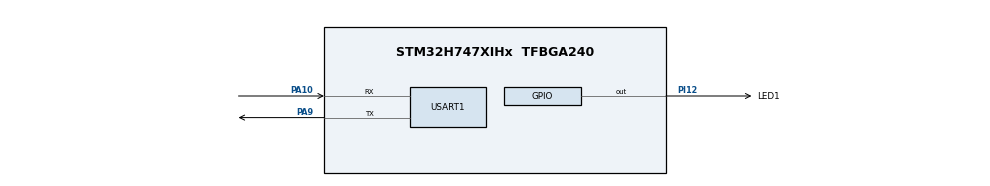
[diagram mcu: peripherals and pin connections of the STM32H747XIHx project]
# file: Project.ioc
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CORTEX_M7.AccessPermission-Cortex_Memory_Protection_Unit_Region1_Settings=MPU_REGION_FULL_ACCESS
CORTEX_M7.BaseAddress-Cortex_Memory_Protection_Unit_Region1_Settings=SDRAM_DEVICE_ADDR
CORTEX_M7.CPU_DCache=Enabled
CORTEX_M7.CPU_ICache=Enabled
CORTEX_M7.DisableExec-Cortex_Memory_Protection_Unit_Region0_Settings=MPU_INSTRUCTION_ACCESS_DISABLE
CORTEX_M7.Enable-Cortex_Memory_Protection_Unit_Region0_Settings=MPU_REGION_ENABLE
CORTEX_M7.Enable-Cortex_Memory_Protection_Unit_Region1_Settings=MPU_REGION_ENABLE
CORTEX_M7.IsCacheable-Cortex_Memory_Protection_Unit_Region1_Settings=MPU_ACCESS_CACHEABLE
CORTEX_M7.IsShareable-Cortex_Memory_Protection_Unit_Region0_Settings=MPU_ACCESS_SHAREABLE
CORTEX_M7.MPU_Control=MPU_PRIVILEGED_DEFAULT
CORTEX_M7.Size-Cortex_Memory_Protection_Unit_Region0_Settings=MPU_REGION_SIZE_4GB
CORTEX_M7.Size-Cortex_Memory_Protection_Unit_Region1_Settings=MPU_REGION_SIZE_32MB
CORTEX_M7.SubRegionDisable-Cortex_Memory_Protection_Unit_Region0_Settings=0x87
CortexM4.IPs=BDMA,DMA,FATFS_M4\:I,FREERTOS_M4\:I,IWDG2\:I,MDMA,NVIC2\:I,RCC,USB_DEVICE_M4\:I,USB_HOST_M4\:I,WWDG2\:I,DEBUG,PDM2PCM_M4\:I,PWR,RESMGR_UTILITY,SYS_M4\:I,CORTEX_M4\:I,OPENAMP_M4\:I,VREFBUF,GPIO
CortexM7.IPs=BDMA\:I,DMA\:I,FATFS_M7\:I,FREERTOS_M7\:I,IWDG1\:I,MDMA\:I,NVIC1\:I,RCC\:I,USB_DEVICE_M7\:I,USB_HOST_M7\:I,WWDG1\:I,CORTEX_M7\:I,DEBUG\:I,PDM2PCM_M7\:I,PWR\:I,RESMGR_UTILITY\:I,SYS\:I,OPENAMP_M7\:I,VREFBUF\:I,GPIO\:I,USART1\:I,STMicroelectronics.X-CUBE-AI.9.0.0_M7\:I,CRC\:I
CortexM7.Pins=PI12
Mcu.Family=STM32H7
Mcu.Name=STM32H747XIHx
Mcu.Package=TFBGA240
NVIC1.PriorityGroup=NVIC_PRIORITYGROUP_4
NVIC2.PriorityGroup=NVIC_PRIORITYGROUP_4
PA10.Mode=Asynchronous
PA10.PinAttribute=CortexM7
PA10.Signal=USART1_RX
PA13\ (JTMS/SWDIO).Mode=Serial_Wire
PA13\ (JTMS/SWDIO).PinAttribute=CortexM7
PA13\ (JTMS/SWDIO).Signal=DEBUG_JTMS-SWDIO
PA14\ (JTCK/SWCLK).Mode=Serial_Wire
PA14\ (JTCK/SWCLK).PinAttribute=CortexM7
PA14\ (JTCK/SWCLK).Signal=DEBUG_JTCK-SWCLK
PA9.Mode=Asynchronous
PA9.PinAttribute=CortexM7
PA9.Signal=USART1_TX
PC14-OSC32_IN\ (OSC32_IN).Mode=LSE-External-Oscillator
PC14-OSC32_IN\ (OSC32_IN).PinAttribute=Free
PC14-OSC32_IN\ (OSC32_IN).Signal=RCC_OSC32_IN
PC15-OSC32_OUT\ (OSC32_OUT).Mode=LSE-External-Oscillator
PC15-OSC32_OUT\ (OSC32_OUT).PinAttribute=Free
PC15-OSC32_OUT\ (OSC32_OUT).Signal=RCC_OSC32_OUT
PH0-OSC_IN\ (PH0).Mode=HSE-External-Oscillator
PH0-OSC_IN\ (PH0).PinAttribute=Free
PH0-OSC_IN\ (PH0).Signal=RCC_OSC_IN
PH1-OSC_OUT\ (PH1).Mode=HSE-External-Oscillator
PH1-OSC_OUT\ (PH1).PinAttribute=Free
PH1-OSC_OUT\ (PH1).Signal=RCC_OSC_OUT
PI12.GPIO_Label=LED1
PI12.PinAttribute=CortexM7
PI12.Signal=GPIO_Output
ProjectManager.HeapSize=M4-0x800,M7-0x800
ProjectManager.StackSize=M4-0x800,M7-0x800
ProjectManager.TargetToolchain=MDK-ARM V5.32
RCC.ADCFreq_Value=75000000
RCC.APB1Freq_Value=100000000
RCC.APB2Freq_Value=100000000
RCC.APB3Freq_Value=100000000
RCC.APB4Freq_Value=100000000
RCC.CortexFreq_Value=400000000
RCC.D1PPRE=RCC_APB3_DIV2
RCC.D2PPRE1=RCC_APB1_DIV2
RCC.D2PPRE2=RCC_APB2_DIV2
RCC.D3PPRE=RCC_APB4_DIV2
RCC.DIVM1=2
RCC.DIVM2=2
RCC.DIVN1=64
RCC.DIVN2=12
RCC.HCLKFreq_Value=200000000
RCC.HPRE=RCC_HCLK_DIV2
RCC.PLL2FRACN=0
RCC.PLLFRACN=0
RCC.PLLSourceVirtual=RCC_PLLSOURCE_HSE
RCC.PWR_Regulator_Voltage_Scale=PWR_REGULATOR_VOLTAGE_SCALE1
RCC.SYSCLKFreq_VALUE=400000000
RCC.SYSCLKSource=RCC_SYSCLKSOURCE_PLLCLK
RCC.SupplySource=PWR_DIRECT_SMPS_SUPPLY
RCC.USBFreq_Value=400000000
STMicroelectronics.X-CUBE-AI.9.0.0_M7.ActivationBufferSizeList=11064
STMicroelectronics.X-CUBE-AI.9.0.0_M7.ActivationBuffers=pool0
STMicroelectronics.X-CUBE-AI.9.0.0_M7.ActivationNames=pool0
STMicroelectronics.X-CUBE-AI.9.0.0_M7.ActivationSizes=AI_NETWORK_DATA_ACTIVATION_1_SIZE
STMicroelectronics.X-CUBE-AI.9.0.0_M7.HeapSize=0x800
STMicroelectronics.X-CUBE-AI.9.0.0_M7.InternalRamActivationBufferMaxSize=AI_NETWORK_DATA_ACTIVATIONS_SIZE
STMicroelectronics.X-CUBE-AI.9.0.0_M7.LatestDirectoryUsed-6234248c4004abe7d7212880ea0172928cda6f889b609eae4421626e04a52cb4=C\:\\Users\\Lenovo\\Documents
STMicroelectronics.X-CUBE-AI.9.0.0_M7.MaximumNumberOfInputLayer=1
STMicroelectronics.X-CUBE-AI.9.0.0_M7.MaximumNumberOfOutputLayer=1
STMicroelectronics.X-CUBE-AI.9.0.0_M7.MaximumSizeOfInputLayer=1
STMicroelectronics.X-CUBE-AI.9.0.0_M7.MaximumSizeOfOutputLayer=1
STMicroelectronics.X-CUBE-AI.9.0.0_M7.ModelActualCompression-6234248c4004abe7d7212880ea0172928cda6f889b609eae4421626e04a52cb4=0.0
STMicroelectronics.X-CUBE-AI.9.0.0_M7.ModelCompression-6234248c4004abe7d7212880ea0172928cda6f889b609eae4421626e04a52cb4=None
STMicroelectronics.X-CUBE-AI.9.0.0_M7.ModelFlashOccupation-6234248c4004abe7d7212880ea0172928cda6f889b609eae4421626e04a52cb4=46304
STMicroelectronics.X-CUBE-AI.9.0.0_M7.ModelHashList=6234248c4004abe7d7212880ea0172928cda6f889b609eae4421626e04a52cb4
STMicroelectronics.X-CUBE-AI.9.0.0_M7.ModelKind-6234248c4004abe7d7212880ea0172928cda6f889b609eae4421626e04a52cb4=ONNX
STMicroelectronics.X-CUBE-AI.9.0.0_M7.ModelMacc-6234248c4004abe7d7212880ea0172928cda6f889b609eae4421626e04a52cb4=481480
STMicroelectronics.X-CUBE-AI.9.0.0_M7.ModelName-6234248c4004abe7d7212880ea0172928cda6f889b609eae4421626e04a52cb4=network
STMicroelectronics.X-CUBE-AI.9.0.0_M7.ModelNameList=network
STMicroelectronics.X-CUBE-AI.9.0.0_M7.ModelRamOccupation-6234248c4004abe7d7212880ea0172928cda6f889b609eae4421626e04a52cb4=11064
STMicroelectronics.X-CUBE-AI.9.0.0_M7.ModelStructureFile-6234248c4004abe7d7212880ea0172928cda6f889b609eae4421626e04a52cb4=C\:\\Users\\Lenovo\\Documents\\model.onnx
STMicroelectronics.X-CUBE-AI.9.0.0_M7.ModelType-6234248c4004abe7d7212880ea0172928cda6f889b609eae4421626e04a52cb4=STM32Cube.AI MCU runtime
STMicroelectronics.X-CUBE-AI.9.0.0_M7.ReadyForCodeGeneration=true
STMicroelectronics.X-CUBE-AI.9.0.0_M7.StackSize=0x800
STMicroelectronics.X-CUBE-AI.9.0.0_M7.WorkingBufferStartAddrList=0xFFFFFFFF
STMicroelectronics.X-CUBE-AI.9.0.0_M7.XAaCUBEAaAICcArtificialOoIntelligenceJjCore=true
STMicroelectronics.X-CUBE-AI.9.0.0_M7.copyWeightToRam=false
STMicroelectronics.X-CUBE-AI.9.0.0_M7.customLayerConfigEnabled=false
STMicroelectronics.X-CUBE-AI.9.0.0_M7.noOnnxIoTranspose=false
STMicroelectronics.X-CUBE-AI.9.0.0_M7.useInputAllocation=true
STMicroelectronics.X-CUBE-AI.9.0.0_M7.useOutputAllocation=true
USART1.VirtualMode-Asynchronous=VM_ASYNC
VP_CRC_VS_CRC.Mode=CRC_Activate
VP_STMicroelectronics.X-CUBE-AI_M7_VS_ArtificialOoIntelligenceJjXAaCUBEAaAI_9.0.0.Mode=ArtificialOoIntelligenceJjXAaCUBEAaAI
VP_SYS_M4_VS_Systick.Mode=SysTick
board=STM32H747I-DISCO

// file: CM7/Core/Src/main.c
/* USER CODE BEGIN Header */
/**
  ******************************************************************************
  * @file           : main.c
  * @brief          : Main program body
  ******************************************************************************
  * @attention
  *
  * Copyright (c) 2024 STMicroelectronics.
  * All rights reserved.
  *
  * This software is licensed under terms that can be found in the LICENSE file
  * in the root directory of this software component.
  * If no LICENSE file comes with this software, it is provided AS-IS.
  *
  ******************************************************************************
  */
/* USER CODE END Header */
#include "main.h"
#include "usart.h"
#include "gpio.h"
#include "network.h"
#include "network_data.h"
#include "crc.h"
/* USER CODE BEGIN Includes */
#include "stm32h747i_discovery.h"
#include "stm32h747i_discovery_lcd.h"
#include "stm32h747i_discovery_sdram.h"
#include "stm32h747i_discovery_bus.h"
#include "stm32h747i_discovery_ts.h"
#include "stm32_lcd.h"
#include "stm32_lcd.h"

#include <string.h>
#include <stdio.h>
/* USER CODE END Includes */

/* USER CODE BEGIN PTD */
#define LCD_FRAME_BUFFER        0xD0000000

extern LTDC_HandleTypeDef hlcd_ltdc;
static DMA2D_HandleTypeDef   hdma2d;
extern DSI_HandleTypeDef hlcd_dsi;
DSI_VidCfgTypeDef hdsivideo_handle;
DSI_CmdCfgTypeDef CmdCfg;
DSI_LPCmdTypeDef LPCmd;
DSI_PLLInitTypeDef dsiPllInit;
static RCC_PeriphCLKInitTypeDef  PeriphClkInitStruct;
OTM8009A_Object_t *pObj;

TS_Init_t *hTS;
/* Global handle to reference the instantiated C-model */
static ai_handle network = AI_HANDLE_NULL;

/* Global c-array to handle the activations buffer */
AI_ALIGNED(32)
static ai_u8 activations[AI_NETWORK_DATA_ACTIVATIONS_SIZE];

/* Array to store the data of the input tensor */
AI_ALIGNED(32)
static ai_float input_data[784];
/* or static ai_u8 in_data[AI_NETWORK_IN_1_SIZE_BYTES]; */

/* c-array to store the data of the output tensor */
AI_ALIGNED(32)
static ai_float output_data[10];
/* static ai_u8 out_data[AI_NETWORK_OUT_1_SIZE_BYTES]; */

/* Array of pointer to manage the model's input/output tensors */
static ai_buffer *ai_input;
static ai_buffer *ai_output;

/* USER CODE END PTD */

/* USER CODE BEGIN PD */

#ifndef HSEM_ID_0
#define HSEM_ID_0 (0U) /* HW semaphore 0*/
#endif

/* USER CODE END PD */

/* USER CODE BEGIN PM */
#define VSYNC               1
#define VBP                 1
#define VFP                 1
#define VACT                480
#define HSYNC               1
#define HBP                 1
#define HFP                 1
#define HACT                800

#define LAYER0_ADDRESS               (LCD_FB_START_ADDRESS)

/* USER CODE END PM */

/* USER CODE BEGIN PV */

uint8_t My_String[60];
TS_State_t  TS_State = {0};
float in_data [28*28];

/* USER CODE END PV */

void SystemClock_Config(void);
static void MPU_Config(void);
/* USER CODE BEGIN PFP */
static void CopyBuffer(uint32_t *pSrc,
                           uint32_t *pDst,
                           uint16_t x,
                           uint16_t y,
                           uint16_t xsize,
                           uint16_t ysize);
static uint8_t LCD_Init(void);
void LTDC_Init(void);

static void LCD_LayertInit(uint16_t LayerIndex, uint32_t Address);
static int32_t DSI_IO_Write(uint16_t ChannelNbr, uint16_t Reg, uint8_t *pData, uint16_t Size);
static int32_t DSI_IO_Read(uint16_t ChannelNbr, uint16_t Reg, uint8_t *pData, uint16_t Size);
int32_t LCD_GetXSize(uint32_t Instance, uint32_t *XSize);
int32_t LCD_GetYSize(uint32_t Instance, uint32_t *YSize);
void LCD_MspInit(void);

static void LCD_BriefDisplay(void);

const LCD_UTILS_Drv_t LCD_UTIL_Driver =
{
  BSP_LCD_DrawBitmap,
  BSP_LCD_FillRGBRect,
  BSP_LCD_DrawHLine,
  BSP_LCD_DrawVLine,
  BSP_LCD_FillRect,
  BSP_LCD_ReadPixel,
  BSP_LCD_WritePixel,
  LCD_GetXSize,
  LCD_GetYSize,
  BSP_LCD_SetActiveLayer,
  BSP_LCD_GetPixelFormat
};
int aiInit(void) {
  ai_error err;

  /* Create and initialize the c-model *//*??????c-model */
  const ai_handle acts[] = { activations };
  err = ai_network_create_and_init(&network, acts, NULL);
  if (err.type != AI_ERROR_NONE) {};

  /* Reteive pointers to the model's input/output tensors *//*????????/???????*/
  ai_input = ai_network_inputs_get(network, NULL);
  ai_output = ai_network_outputs_get(network, NULL);

  return 0;
}
void AI_Run()
{
  ai_i32 batch;
  ai_error err;

  /* Update IO handlers with the data payload */
  ai_input[0].data = AI_HANDLE_PTR(input_data);
  ai_output[0].data = AI_HANDLE_PTR(output_data);

  batch = ai_network_run(network, ai_input, ai_output);
  if (batch != 1) {
    err = ai_network_get_error(network);
    Error_Handler();
  }
 }

/* USER CODE END PFP */

int main(void)
{

/* USER CODE BEGIN Boot_Mode_Sequence_0 */
  int32_t timeout;
/* USER CODE END Boot_Mode_Sequence_0 */

  /* MPU Configuration--------------------------------------------------------*/
  MPU_Config();

  /* Enable the CPU Cache */

  /* Enable I-Cache---------------------------------------------------------*/
  SCB_EnableICache();

  /* Enable D-Cache---------------------------------------------------------*/
  SCB_EnableDCache();

/* USER CODE BEGIN Boot_Mode_Sequence_1 */
  /* Wait until CPU2 boots and enters in stop mode or timeout*/
  timeout = 0xFFFF;
  while((__HAL_RCC_GET_FLAG(RCC_FLAG_D2CKRDY) != RESET) && (timeout-- > 0));
  if ( timeout < 0 )
  {
  Error_Handler();
  }
/* USER CODE END Boot_Mode_Sequence_1 */
  /* MCU Configuration--------------------------------------------------------*/

  /* Reset of all peripherals, Initializes the Flash interface and the Systick. */
  HAL_Init();

  /* Configure the system clock */
  SystemClock_Config();
/* USER CODE BEGIN Boot_Mode_Sequence_2 */
/* When system initialization is finished, Cortex-M7 will release Cortex-M4 by means of
HSEM notification */
/*HW semaphore Clock enable*/
__HAL_RCC_HSEM_CLK_ENABLE();
/*Take HSEM */
HAL_HSEM_FastTake(HSEM_ID_0);
/*Release HSEM in order to notify the CPU2(CM4)*/
HAL_HSEM_Release(HSEM_ID_0,0);
/* wait until CPU2 wakes up from stop mode */
timeout = 0xFFFF;
while((__HAL_RCC_GET_FLAG(RCC_FLAG_D2CKRDY) == RESET) && (timeout-- > 0));
if ( timeout < 0 )
{
Error_Handler();
}
/* USER CODE END Boot_Mode_Sequence_2 */

  /* Initialize all configured peripherals */
  MX_GPIO_Init();
  MX_USART1_UART_Init();
  MX_CRC_Init();
  aiInit();
  /* USER CODE BEGIN 2 */
  /* Initialize used Leds */
  BSP_LED_Init(LED3);

  /* Initialize the SDRAM */
  BSP_SDRAM_Init(0);

  /* Initialize the LCD   */
  if( LCD_Init() != BSP_ERROR_NONE)
  {
    Error_Handler();
  }

	/* Set the LCD Context */
  Lcd_Ctx[0].ActiveLayer = 0;
  Lcd_Ctx[0].PixelFormat = LCD_PIXEL_FORMAT_ARGB8888;
  Lcd_Ctx[0].BppFactor = 4; /* 4 Bytes Per Pixel for ARGB8888 */
  Lcd_Ctx[0].XSize = 800;
  Lcd_Ctx[0].YSize = 480;
  /* Disable DSI Wrapper in order to access and configure the LTDC */
  __HAL_DSI_WRAPPER_DISABLE(&hlcd_dsi);

  /* Initialize LTDC layer 0 iused for Hint */
  LCD_LayertInit(0, LCD_FRAME_BUFFER);
  UTIL_LCD_SetFuncDriver(&LCD_UTIL_Driver);

  /* Enable DSI Wrapper so DSI IP will drive the LTDC */
  __HAL_DSI_WRAPPER_ENABLE(&hlcd_dsi);

  /* Display example brief   */
  LCD_BriefDisplay();

  /*Refresh the LCD display*/
  HAL_DSI_Refresh(&hlcd_dsi);  //?üD?íê3éoó??2úéú?D??????è??D??·t??3ìDò??

  /* Touchscreen initialization */
	uint32_t ts_status = BSP_ERROR_NONE;
  uint32_t x_size, y_size;

  BSP_LCD_GetXSize(0, &x_size);
  BSP_LCD_GetYSize(0, &y_size);
  hTS->Width = x_size;
  hTS->Height = y_size;
  hTS->Orientation = TS_SWAP_XY | TS_SWAP_Y;
  hTS->Accuracy = 0;

  ts_status = BSP_TS_Init(0, hTS);
  if(ts_status == BSP_ERROR_NONE)
  {
    /* Display touch screen demo description */
		UTIL_LCD_FillRect(0, 0, 800, 120, UTIL_LCD_COLOR_WHITE);
		UTIL_LCD_FillRect(200, 40, 400, 50, UTIL_LCD_COLOR_RED);
		UTIL_LCD_FillRect(205, 45, 390, 40, UTIL_LCD_COLOR_BLUE);
		UTIL_LCD_DisplayStringAt(300,60,(uint8_t*) "Handwriting Predict", LEFT_MODE);
		UTIL_LCD_FillRect(50, 150, 280, 280, UTIL_LCD_COLOR_BLACK);  //ó?óú'??t?áê?D'
		UTIL_LCD_DisplayStringAt(400,350,(uint8_t*) "Guess:", LEFT_MODE); //ê?±e?á1???ê???×?'ó?é?ü
		//UTIL_LCD_DisplayStringAt(600,350,(uint8_t*) "Second Guess:", LEFT_MODE); //ê?±e?á1???ê?????'??é?ü
		UTIL_LCD_SetTextColor(UTIL_LCD_COLOR_YELLOW);
		UTIL_LCD_FillRect(400, 150, 150, 50, UTIL_LCD_COLOR_RED);   // è???°'??
		UTIL_LCD_FillRect(405, 155, 140, 40, UTIL_LCD_COLOR_BLUE);  // è???°'??
		UTIL_LCD_DisplayStringAt(405,170,(uint8_t*) "    CLEAR  ", LEFT_MODE);
		UTIL_LCD_FillRect(400, 250, 150, 50, UTIL_LCD_COLOR_RED);   // ?¤2a°'??
		UTIL_LCD_FillRect(405, 255, 140, 40, UTIL_LCD_COLOR_BLUE);  // ?¤2a°'??
		UTIL_LCD_DisplayStringAt(405,270,(uint8_t*) "   PREDICT ", LEFT_MODE);
		HAL_DSI_Refresh(&hlcd_dsi);  //?üD?íê3éoó??2úéú?D??????è??D??·t??3ìDò??
	}
  /* USER CODE END 2 */

  /* Infinite loop */
  /* USER CODE BEGIN WHILE */
  while (1)
  {
//      /* Check in polling mode in touch screen the touch status and coordinates */
//      /* of touches if touch occurred                                           */
      ts_status = BSP_TS_GetState(0, &TS_State);
      if(TS_State.TouchDetected)
      {
        /* One or dual touch have been detected          */
        /* Only take into account the first touch so far */
				if(TS_State.TouchX>50&&TS_State.TouchX<330&&TS_State.TouchY>150&&TS_State.TouchY<430)
				{
					in_data[(TS_State.TouchX-50)/10+((TS_State.TouchY-150)/10)*28]=(float)255;
          in_data[((TS_State.TouchX-50)/10+1)+((TS_State.TouchY-150)/10)*28]=(float)255;
          in_data[(TS_State.TouchX-50)/10+((TS_State.TouchY-150)/10+1)*28]=(float)255;
          in_data[((TS_State.TouchX-50)/10+1)+((TS_State.TouchY-150)/10+1)*28]=(float)255;
					UTIL_LCD_FillCircle(TS_State.TouchX,TS_State.TouchY,4, UTIL_LCD_COLOR_WHITE );
					HAL_DSI_Refresh(&hlcd_dsi);
				}
				else if(TS_State.TouchX>400&&TS_State.TouchX<550&&TS_State.TouchY>150&&TS_State.TouchY<200)
				{
					UTIL_LCD_FillRect(50, 150, 280, 280, UTIL_LCD_COLOR_BLACK);
					for(int i=0;i<784;i++){	in_data[i]=0;}
					HAL_DSI_Refresh(&hlcd_dsi);
					UTIL_LCD_FillRect(600, 350, 100, 100, UTIL_LCD_COLOR_WHITE);
				}
				else if(TS_State.TouchX>400&&TS_State.TouchX<550&&TS_State.TouchY>250&&TS_State.TouchY<300)
				{
					//???¯ê?D'ê?±e??·¨??'yíê3é?
					for(int i=0;i<784;i++){
						input_data[i]=in_data[i];
					}
					AI_Run();
					/*char s[]="0";
					int i,j,a=0,b=0;
					int k[28]={0};
					for(i=0;i<28;i++){
						for(j=0;j<28;j++){
							if(in_data[i*28+j]==1)
								k[i]++;
						}
						if(k[i]>1)
							a++;
					}*/
					float t;
					int num;
					num=0;
					t=output_data[0];
					for(int i;i<10;i++){
						if(output_data[i]>t){
							t=output_data[i];
							num=i;
						}
					}
					HAL_DSI_Refresh(&hlcd_dsi);
					if(num==0)
					  UTIL_LCD_DisplayStringAt(600,350,(uint8_t*) "0", LEFT_MODE);
					else if(num==1)
						UTIL_LCD_DisplayStringAt(600,350,(uint8_t*) "1", LEFT_MODE);
				  else if(num==2)
						UTIL_LCD_DisplayStringAt(600,350,(uint8_t*) "2", LEFT_MODE);
					else if(num==3)
						UTIL_LCD_DisplayStringAt(600,350,(uint8_t*) "3", LEFT_MODE);
					else if(num==4)
						UTIL_LCD_DisplayStringAt(600,350,(uint8_t*) "4", LEFT_MODE);
					else if(num==5)
						UTIL_LCD_DisplayStringAt(600,350,(uint8_t*) "5", LEFT_MODE);
					else if(num==6)
						UTIL_LCD_DisplayStringAt(600,350,(uint8_t*) "6", LEFT_MODE);
					else if(num==7)
						UTIL_LCD_DisplayStringAt(600,350,(uint8_t*) "7", LEFT_MODE);
					else if(num==8)
						UTIL_LCD_DisplayStringAt(600,350,(uint8_t*) "8", LEFT_MODE);
					else
						UTIL_LCD_DisplayStringAt(600,350,(uint8_t*) "9", LEFT_MODE);

					HAL_Delay(500);  //±ü?a°'??°'???à'????'?'DD?¤2a??
					HAL_DSI_Refresh(&hlcd_dsi);
				}
			}
    /* USER CODE END WHILE */

  }
}

void SystemClock_Config(void)
{
  RCC_OscInitTypeDef RCC_OscInitStruct = {0};
  RCC_ClkInitTypeDef RCC_ClkInitStruct = {0};

  /** Supply configuration update enable
  */
  HAL_PWREx_ConfigSupply(PWR_DIRECT_SMPS_SUPPLY);

  /** Configure the main internal regulator output voltage
  */
  __HAL_PWR_VOLTAGESCALING_CONFIG(PWR_REGULATOR_VOLTAGE_SCALE1);

  while(!__HAL_PWR_GET_FLAG(PWR_FLAG_VOSRDY)) {}

  /** Initializes the RCC Oscillators according to the specified parameters
  * in the RCC_OscInitTypeDef structure.
  */
  RCC_OscInitStruct.OscillatorType = RCC_OSCILLATORTYPE_HSE;
  RCC_OscInitStruct.HSEState = RCC_HSE_ON;
  RCC_OscInitStruct.PLL.PLLState = RCC_PLL_ON;
  RCC_OscInitStruct.PLL.PLLSource = RCC_PLLSOURCE_HSE;
  RCC_OscInitStruct.PLL.PLLM = 2;
  RCC_OscInitStruct.PLL.PLLN = 64;
  RCC_OscInitStruct.PLL.PLLP = 2;
  RCC_OscInitStruct.PLL.PLLQ = 2;
  RCC_OscInitStruct.PLL.PLLR = 2;
  RCC_OscInitStruct.PLL.PLLRGE = RCC_PLL1VCIRANGE_3;
  RCC_OscInitStruct.PLL.PLLVCOSEL = RCC_PLL1VCOWIDE;
  RCC_OscInitStruct.PLL.PLLFRACN = 0;
  if (HAL_RCC_OscConfig(&RCC_OscInitStruct) != HAL_OK)
  {
    Error_Handler();
  }

  /** Initializes the CPU, AHB and APB buses clocks
  */
  RCC_ClkInitStruct.ClockType = RCC_CLOCKTYPE_HCLK|RCC_CLOCKTYPE_SYSCLK
                              |RCC_CLOCKTYPE_PCLK1|RCC_CLOCKTYPE_PCLK2
                              |RCC_CLOCKTYPE_D3PCLK1|RCC_CLOCKTYPE_D1PCLK1;
  RCC_ClkInitStruct.SYSCLKSource = RCC_SYSCLKSOURCE_PLLCLK;
  RCC_ClkInitStruct.SYSCLKDivider = RCC_SYSCLK_DIV1;
  RCC_ClkInitStruct.AHBCLKDivider = RCC_HCLK_DIV2;
  RCC_ClkInitStruct.APB3CLKDivider = RCC_APB3_DIV2;
  RCC_ClkInitStruct.APB1CLKDivider = RCC_APB1_DIV2;
  RCC_ClkInitStruct.APB2CLKDivider = RCC_APB2_DIV2;
  RCC_ClkInitStruct.APB4CLKDivider = RCC_APB4_DIV2;

  if (HAL_RCC_ClockConfig(&RCC_ClkInitStruct, FLASH_LATENCY_2) != HAL_OK)
  {
    Error_Handler();
  }
}

/* USER CODE BEGIN 4 */
/**
  * @brief  Gets the LCD X size.
  * @param  Instance  LCD Instance
  * @param  XSize     LCD width
  * @retval BSP status
  */
int32_t LCD_GetXSize(uint32_t Instance, uint32_t *XSize)
{
  *XSize = Lcd_Ctx[0].XSize;

  return BSP_ERROR_NONE;
}

/**
  * @brief  Gets the LCD Y size.
  * @param  Instance  LCD Instance
  * @param  YSize     LCD Height
  * @retval BSP status
  */
int32_t LCD_GetYSize(uint32_t Instance, uint32_t *YSize)
{
  *YSize = Lcd_Ctx[0].YSize;

  return BSP_ERROR_NONE;
}
/**
  * @brief  End of Refresh DSI callback.
  * @param  hdsi: pointer to a DSI_HandleTypeDef structure that contains
  *               the configuration information for the DSI.
  * @retval None
  */
void HAL_DSI_EndOfRefreshCallback(DSI_HandleTypeDef *hdsi)
{
//  if(pending_buffer >= 0)
//  {
//    pending_buffer = -1;
//  }
}

/**
  * @brief  Initializes the DSI LCD.
  * The ititialization is done as below:
  *     - DSI PLL ititialization
  *     - DSI ititialization
  *     - LTDC ititialization
  *     - OTM8009A LCD Display IC Driver ititialization
  * @param  None
  * @retval LCD state
  */
static uint8_t LCD_Init(void)
{
  DSI_PHY_TimerTypeDef  PhyTimings;
  OTM8009A_IO_t              IOCtx;
  static OTM8009A_Object_t   OTM8009AObj;
  static void                *Lcd_CompObj = NULL;

  /* Toggle Hardware Reset of the DSI LCD using
     its XRES signal (active low) */
  BSP_LCD_Reset(0);

  /* Call first MSP Initialize only in case of first initialization
  * This will set IP blocks LTDC, DSI and DMA2D
  * - out of reset
  * - clocked
  * - NVIC IRQ related to IP blocks enabled
  */
  LCD_MspInit();

  /* LCD clock configuration */
  /* LCD clock configuration */
  /* PLL3_VCO Input = HSE_VALUE/PLL3M = 5 Mhz */
  /* PLL3_VCO Output = PLL3_VCO Input * PLL3N = 800 Mhz */
  /* PLLLCDCLK = PLL3_VCO Output/PLL3R = 800/19 = 42 Mhz */
  /* LTDC clock frequency = PLLLCDCLK = 42 Mhz */
  PeriphClkInitStruct.PeriphClockSelection = RCC_PERIPHCLK_LTDC;
  PeriphClkInitStruct.PLL3.PLL3M = 5;
  PeriphClkInitStruct.PLL3.PLL3N = 160;
  PeriphClkInitStruct.PLL3.PLL3FRACN = 0;
  PeriphClkInitStruct.PLL3.PLL3P = 2;
  PeriphClkInitStruct.PLL3.PLL3Q = 2;
  PeriphClkInitStruct.PLL3.PLL3R = 19;
  PeriphClkInitStruct.PLL3.PLL3VCOSEL = RCC_PLL3VCOWIDE;
  PeriphClkInitStruct.PLL3.PLL3RGE = RCC_PLL3VCIRANGE_2;
  HAL_RCCEx_PeriphCLKConfig(&PeriphClkInitStruct);

  /* Base address of DSI Host/Wrapper registers to be set before calling De-Init */
  hlcd_dsi.Instance = DSI;

  HAL_DSI_DeInit(&(hlcd_dsi));

  dsiPllInit.PLLNDIV  = 100;
  dsiPllInit.PLLIDF   = DSI_PLL_IN_DIV5;
  dsiPllInit.PLLODF  = DSI_PLL_OUT_DIV1;

  hlcd_dsi.Init.NumberOfLanes = DSI_TWO_DATA_LANES;
  hlcd_dsi.Init.TXEscapeCkdiv = 0x4;

  HAL_DSI_Init(&(hlcd_dsi), &(dsiPllInit));

  /* Configure the DSI for Command mode */
  CmdCfg.VirtualChannelID      = 0;
  CmdCfg.HSPolarity            = DSI_HSYNC_ACTIVE_HIGH;
  CmdCfg.VSPolarity            = DSI_VSYNC_ACTIVE_HIGH;
  CmdCfg.DEPolarity            = DSI_DATA_ENABLE_ACTIVE_HIGH;
  CmdCfg.ColorCoding           = DSI_RGB888;
  CmdCfg.CommandSize           = HACT;
  CmdCfg.TearingEffectSource   = DSI_TE_DSILINK;
  CmdCfg.TearingEffectPolarity = DSI_TE_RISING_EDGE;
  CmdCfg.VSyncPol              = DSI_VSYNC_FALLING;
  CmdCfg.AutomaticRefresh      = DSI_AR_DISABLE;
  CmdCfg.TEAcknowledgeRequest  = DSI_TE_ACKNOWLEDGE_ENABLE;
  HAL_DSI_ConfigAdaptedCommandMode(&hlcd_dsi, &CmdCfg);

  LPCmd.LPGenShortWriteNoP    = DSI_LP_GSW0P_ENABLE;
  LPCmd.LPGenShortWriteOneP   = DSI_LP_GSW1P_ENABLE;
  LPCmd.LPGenShortWriteTwoP   = DSI_LP_GSW2P_ENABLE;
  LPCmd.LPGenShortReadNoP     = DSI_LP_GSR0P_ENABLE;
  LPCmd.LPGenShortReadOneP    = DSI_LP_GSR1P_ENABLE;
  LPCmd.LPGenShortReadTwoP    = DSI_LP_GSR2P_ENABLE;
  LPCmd.LPGenLongWrite        = DSI_LP_GLW_ENABLE;
  LPCmd.LPDcsShortWriteNoP    = DSI_LP_DSW0P_ENABLE;
  LPCmd.LPDcsShortWriteOneP   = DSI_LP_DSW1P_ENABLE;
  LPCmd.LPDcsShortReadNoP     = DSI_LP_DSR0P_ENABLE;
  LPCmd.LPDcsLongWrite        = DSI_LP_DLW_ENABLE;
  HAL_DSI_ConfigCommand(&hlcd_dsi, &LPCmd);

  /* Initialize LTDC */
  LTDC_Init();

  /* Start DSI */
  HAL_DSI_Start(&(hlcd_dsi));

  /* Configure DSI PHY HS2LP and LP2HS timings */
  PhyTimings.ClockLaneHS2LPTime = 35;
  PhyTimings.ClockLaneLP2HSTime = 35;
  PhyTimings.DataLaneHS2LPTime = 35;
  PhyTimings.DataLaneLP2HSTime = 35;
  PhyTimings.DataLaneMaxReadTime = 0;
  PhyTimings.StopWaitTime = 10;
  HAL_DSI_ConfigPhyTimer(&hlcd_dsi, &PhyTimings);

  /* Initialize the OTM8009A LCD Display IC Driver (KoD LCD IC Driver) */
  IOCtx.Address     = 0;
  IOCtx.GetTick     = BSP_GetTick;
  IOCtx.WriteReg    = DSI_IO_Write;
  IOCtx.ReadReg     = DSI_IO_Read;
  OTM8009A_RegisterBusIO(&OTM8009AObj, &IOCtx);
  Lcd_CompObj=(&OTM8009AObj);
  OTM8009A_Init(Lcd_CompObj, OTM8009A_COLMOD_RGB888, LCD_ORIENTATION_LANDSCAPE);

  LPCmd.LPGenShortWriteNoP    = DSI_LP_GSW0P_DISABLE;
  LPCmd.LPGenShortWriteOneP   = DSI_LP_GSW1P_DISABLE;
  LPCmd.LPGenShortWriteTwoP   = DSI_LP_GSW2P_DISABLE;
  LPCmd.LPGenShortReadNoP     = DSI_LP_GSR0P_DISABLE;
  LPCmd.LPGenShortReadOneP    = DSI_LP_GSR1P_DISABLE;
  LPCmd.LPGenShortReadTwoP    = DSI_LP_GSR2P_DISABLE;
  LPCmd.LPGenLongWrite        = DSI_LP_GLW_DISABLE;
  LPCmd.LPDcsShortWriteNoP    = DSI_LP_DSW0P_DISABLE;
  LPCmd.LPDcsShortWriteOneP   = DSI_LP_DSW1P_DISABLE;
  LPCmd.LPDcsShortReadNoP     = DSI_LP_DSR0P_DISABLE;
  LPCmd.LPDcsLongWrite        = DSI_LP_DLW_DISABLE;
  HAL_DSI_ConfigCommand(&hlcd_dsi, &LPCmd);

  HAL_DSI_ConfigFlowControl(&hlcd_dsi, DSI_FLOW_CONTROL_BTA);
  HAL_DSI_ForceRXLowPower(&hlcd_dsi, ENABLE);

  return BSP_ERROR_NONE;
}

/**
  * @brief
  * @param  None
  * @retval None
  */
void LTDC_Init(void)
{
  /* DeInit */
  hlcd_ltdc.Instance = LTDC;
  HAL_LTDC_DeInit(&hlcd_ltdc);

  /* LTDC Config */
  /* Timing and polarity */
  hlcd_ltdc.Init.HorizontalSync = HSYNC;
  hlcd_ltdc.Init.VerticalSync = VSYNC;
  hlcd_ltdc.Init.AccumulatedHBP = HSYNC+HBP;
  hlcd_ltdc.Init.AccumulatedVBP = VSYNC+VBP;
  hlcd_ltdc.Init.AccumulatedActiveH = VSYNC+VBP+VACT;
  hlcd_ltdc.Init.AccumulatedActiveW = HSYNC+HBP+HACT;
  hlcd_ltdc.Init.TotalHeigh = VSYNC+VBP+VACT+VFP;
  hlcd_ltdc.Init.TotalWidth = HSYNC+HBP+HACT+HFP;

  /* background value */
  hlcd_ltdc.Init.Backcolor.Blue = 0;
  hlcd_ltdc.Init.Backcolor.Green = 0;
  hlcd_ltdc.Init.Backcolor.Red = 0;

  /* Polarity */
  hlcd_ltdc.Init.HSPolarity = LTDC_HSPOLARITY_AL;
  hlcd_ltdc.Init.VSPolarity = LTDC_VSPOLARITY_AL;
  hlcd_ltdc.Init.DEPolarity = LTDC_DEPOLARITY_AL;
  hlcd_ltdc.Init.PCPolarity = LTDC_PCPOLARITY_IPC;
  hlcd_ltdc.Instance = LTDC;

  HAL_LTDC_Init(&hlcd_ltdc);
}

/**
  * @brief  Initializes the LCD layers.
  * @param  LayerIndex: Layer foreground or background
  * @param  FB_Address: Layer frame buffer
  * @retval None
  */
static void LCD_LayertInit(uint16_t LayerIndex, uint32_t Address)
{
  LTDC_LayerCfgTypeDef  layercfg;

  /* Layer Init */
  layercfg.WindowX0 = 0;
  layercfg.WindowX1 = Lcd_Ctx[0].XSize ;
  layercfg.WindowY0 = 0;
  layercfg.WindowY1 = Lcd_Ctx[0].YSize;
  layercfg.PixelFormat = LTDC_PIXEL_FORMAT_ARGB8888;
  layercfg.FBStartAdress = Address;
  layercfg.Alpha = 255;
  layercfg.Alpha0 = 0;
  layercfg.Backcolor.Blue = 0;
  layercfg.Backcolor.Green = 0;
  layercfg.Backcolor.Red = 0;
  layercfg.BlendingFactor1 = LTDC_BLENDING_FACTOR1_PAxCA;
  layercfg.BlendingFactor2 = LTDC_BLENDING_FACTOR2_PAxCA;
  layercfg.ImageWidth = Lcd_Ctx[0].XSize;
  layercfg.ImageHeight = Lcd_Ctx[0].YSize;

  HAL_LTDC_ConfigLayer(&hlcd_ltdc, &layercfg, LayerIndex);
}

/**
  * @brief  DCS or Generic short/long write command
  * @param  ChannelNbr Virtual channel ID
  * @param  Reg Register to be written
  * @param  pData pointer to a buffer of data to be write
  * @param  Size To precise command to be used (short or long)
  * @retval BSP status
  */
static int32_t DSI_IO_Write(uint16_t ChannelNbr, uint16_t Reg, uint8_t *pData, uint16_t Size)
{
  int32_t ret = BSP_ERROR_NONE;

  if(Size <= 1U)
  {
    if(HAL_DSI_ShortWrite(&hlcd_dsi, ChannelNbr, DSI_DCS_SHORT_PKT_WRITE_P1, Reg, (uint32_t)pData[Size]) != HAL_OK)
    {
      ret = BSP_ERROR_BUS_FAILURE;
    }
  }
  else
  {
    if(HAL_DSI_LongWrite(&hlcd_dsi, ChannelNbr, DSI_DCS_LONG_PKT_WRITE, Size, (uint32_t)Reg, pData) != HAL_OK)
    {
      ret = BSP_ERROR_BUS_FAILURE;
    }
  }

  return ret;
}

/**
  * @brief  DCS or Generic read command
  * @param  ChannelNbr Virtual channel ID
  * @param  Reg Register to be read
  * @param  pData pointer to a buffer to store the payload of a read back operation.
  * @param  Size  Data size to be read (in byte).
  * @retval BSP status
  */
static int32_t DSI_IO_Read(uint16_t ChannelNbr, uint16_t Reg, uint8_t *pData, uint16_t Size)
{
  int32_t ret = BSP_ERROR_NONE;

  if(HAL_DSI_Read(&hlcd_dsi, ChannelNbr, pData, Size, DSI_DCS_SHORT_PKT_READ, Reg, pData) != HAL_OK)
  {
    ret = BSP_ERROR_BUS_FAILURE;
  }

  return ret;
}

void LCD_MspInit(void)
{
  /** @brief Enable the LTDC clock */
  __HAL_RCC_LTDC_CLK_ENABLE();

  /** @brief Toggle Sw reset of LTDC IP */
  __HAL_RCC_LTDC_FORCE_RESET();
  __HAL_RCC_LTDC_RELEASE_RESET();

  /** @brief Enable the DMA2D clock */
  __HAL_RCC_DMA2D_CLK_ENABLE();

  /** @brief Toggle Sw reset of DMA2D IP */
  __HAL_RCC_DMA2D_FORCE_RESET();
  __HAL_RCC_DMA2D_RELEASE_RESET();

  /** @brief Enable DSI Host and wrapper clocks */
  __HAL_RCC_DSI_CLK_ENABLE();

  /** @brief Soft Reset the DSI Host and wrapper */
  __HAL_RCC_DSI_FORCE_RESET();
  __HAL_RCC_DSI_RELEASE_RESET();

  /** @brief NVIC configuration for LTDC interrupt that is now enabled */
  HAL_NVIC_SetPriority(LTDC_IRQn, 9, 0xf);
  HAL_NVIC_EnableIRQ(LTDC_IRQn);

  /** @brief NVIC configuration for DMA2D interrupt that is now enabled */
  HAL_NVIC_SetPriority(DMA2D_IRQn, 9, 0xf);
  HAL_NVIC_EnableIRQ(DMA2D_IRQn);

  /** @brief NVIC configuration for DSI interrupt that is now enabled */
  HAL_NVIC_SetPriority(DSI_IRQn, 9, 0xf);
  HAL_NVIC_EnableIRQ(DSI_IRQn);
}
/**
  * @brief  Display Example description.
  * @param  None
  * @retval None
  */
static void LCD_BriefDisplay(void)
{
  UTIL_LCD_SetFont(&Font24);
  UTIL_LCD_FillRect(0, 0, 800, 112, UTIL_LCD_COLOR_BLUE);  //·??òà?126DD×?·????ùDè??ó??????o24+24+16+16+16+16 = 112
  UTIL_LCD_SetTextColor(UTIL_LCD_COLOR_WHITE);
  UTIL_LCD_FillRect(0, 112, 800, 368, UTIL_LCD_COLOR_WHITE);  //112+368 = 480??LCDµ?'1?±????
  UTIL_LCD_SetBackColor(UTIL_LCD_COLOR_BLUE);
  UTIL_LCD_DisplayStringAtLine(1, (uint8_t *)"     LCD_DSI Display and Touch Sreen Test");  //×?·?'óµú1DD?aê???ê???
  UTIL_LCD_SetFont(&Font16);
  UTIL_LCD_DisplayStringAtLine(4, (uint8_t *)"This example shows how to display images on LCD DSI using same buffer");
  UTIL_LCD_DisplayStringAtLine(5, (uint8_t *)"for display and for draw with Touch Screen   ");

}

/**
  * @brief  Converts a line to an ARGB8888 pixel format.
  * @param  pSrc: Pointer to source buffer
  * @param  pDst: Output color
  * @param  xSize: Buffer width
  * @param  ColorMode: Input color mode
  * @retval None
  */
static void CopyBuffer(uint32_t *pSrc, uint32_t *pDst, uint16_t x, uint16_t y, uint16_t xsize, uint16_t ysize)
{
   uint32_t destination = (uint32_t)pDst + (y * 800 + x) * 4;
  uint32_t source      = (uint32_t)pSrc;

  /*##-1- Configure the DMA2D Mode, Color Mode and output offset #############*/
  hdma2d.Init.Mode         = DMA2D_M2M;
  hdma2d.Init.ColorMode    = DMA2D_OUTPUT_ARGB8888;
  hdma2d.Init.OutputOffset = 800 - xsize;
  hdma2d.Init.AlphaInverted = DMA2D_REGULAR_ALPHA;  /* No Output Alpha Inversion*/
  hdma2d.Init.RedBlueSwap   = DMA2D_RB_REGULAR;     /* No Output Red & Blue swap */

  /*##-2- DMA2D Callbacks Configuration ######################################*/
  hdma2d.XferCpltCallback  = NULL;

  /*##-3- Foreground Configuration ###########################################*/
  hdma2d.LayerCfg[1].AlphaMode = DMA2D_NO_MODIF_ALPHA;
  hdma2d.LayerCfg[1].InputAlpha = 0xFF;
  hdma2d.LayerCfg[1].InputColorMode = DMA2D_INPUT_ARGB8888;
  hdma2d.LayerCfg[1].InputOffset = 0;
  hdma2d.LayerCfg[1].RedBlueSwap = DMA2D_RB_REGULAR; /* No ForeGround Red/Blue swap */
  hdma2d.LayerCfg[1].AlphaInverted = DMA2D_REGULAR_ALPHA; /* No ForeGround Alpha inversion */

  hdma2d.Instance          = DMA2D;

  /* DMA2D Initialization */
  if(HAL_DMA2D_Init(&hdma2d) == HAL_OK)
  {
    if(HAL_DMA2D_ConfigLayer(&hdma2d, 1) == HAL_OK)
    {
      if (HAL_DMA2D_Start(&hdma2d, source, destination, xsize, ysize) == HAL_OK)
      {
        /* Polling For DMA transfer */
        HAL_DMA2D_PollForTransfer(&hdma2d, 100);
      }
    }
  }
}

/******************************************************************************/
/*                 STM32H7xx Peripherals Interrupt Handlers                   */
/*  Add here the Interrupt Handler for the used peripheral(s) (PPP), for the  */
/*  available peripheral interrupt handler's name please refer to the startup */
/*  file (startup_stm32h7xx.s).                                               */
/******************************************************************************/
/**
  * @brief  This function handles DSI Handler.
  * @param  None
  * @retval None
  */
void DSI_IRQHandler(void)
{
  HAL_DSI_IRQHandler(&hlcd_dsi);
}

/* USER CODE END 4 */

 /* MPU Configuration */

void MPU_Config(void)
{
  MPU_Region_InitTypeDef MPU_InitStruct = {0};

  /* Disables the MPU */
  HAL_MPU_Disable();

  /** Initializes and configures the Region and the memory to be protected
  */
  MPU_InitStruct.Enable = MPU_REGION_ENABLE;
  MPU_InitStruct.Number = MPU_REGION_NUMBER0;
  MPU_InitStruct.BaseAddress = 0x0;
  MPU_InitStruct.Size = MPU_REGION_SIZE_4GB;
  MPU_InitStruct.SubRegionDisable = 0x87;
  MPU_InitStruct.TypeExtField = MPU_TEX_LEVEL0;
  MPU_InitStruct.AccessPermission = MPU_REGION_NO_ACCESS;
  MPU_InitStruct.DisableExec = MPU_INSTRUCTION_ACCESS_DISABLE;
  MPU_InitStruct.IsShareable = MPU_ACCESS_SHAREABLE;
  MPU_InitStruct.IsCacheable = MPU_ACCESS_NOT_CACHEABLE;
  MPU_InitStruct.IsBufferable = MPU_ACCESS_NOT_BUFFERABLE;

  HAL_MPU_ConfigRegion(&MPU_InitStruct);

  /** Initializes and configures the Region and the memory to be protected
  */
  MPU_InitStruct.Number = MPU_REGION_NUMBER1;
  MPU_InitStruct.BaseAddress = SDRAM_DEVICE_ADDR;
  MPU_InitStruct.Size = MPU_REGION_SIZE_32MB;
  MPU_InitStruct.SubRegionDisable = 0x0;
  MPU_InitStruct.AccessPermission = MPU_REGION_FULL_ACCESS;
  MPU_InitStruct.DisableExec = MPU_INSTRUCTION_ACCESS_ENABLE;
  MPU_InitStruct.IsShareable = MPU_ACCESS_NOT_SHAREABLE;
  MPU_InitStruct.IsCacheable = MPU_ACCESS_CACHEABLE;

  HAL_MPU_ConfigRegion(&MPU_InitStruct);
  /* Enables the MPU */
  HAL_MPU_Enable(MPU_PRIVILEGED_DEFAULT);

}

void Error_Handler(void)
{
  __disable_irq();
  while (1)
  {
  }
}
